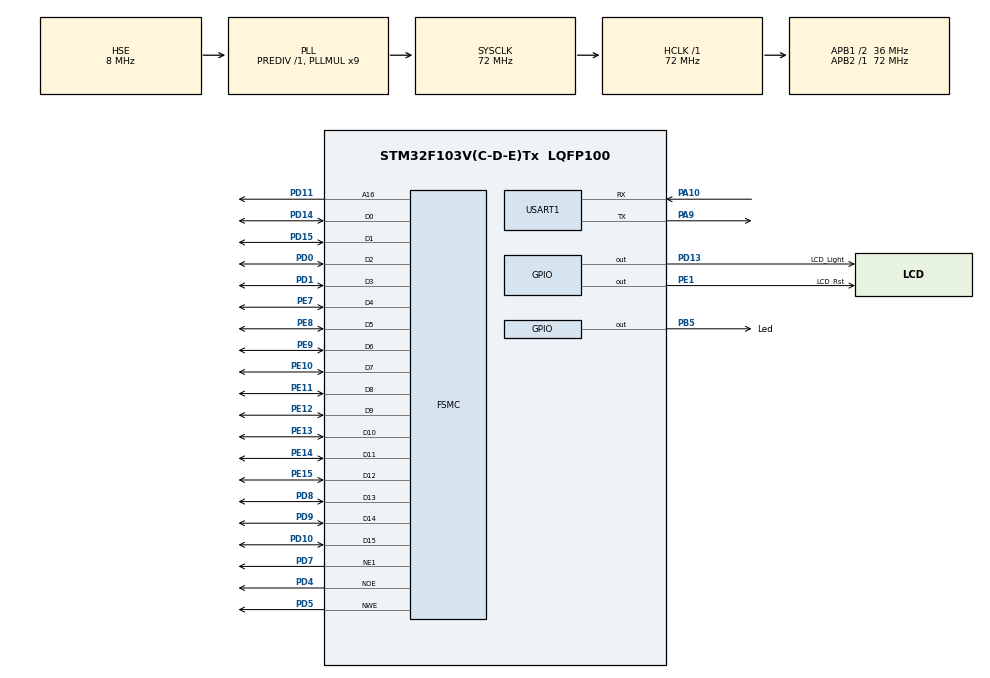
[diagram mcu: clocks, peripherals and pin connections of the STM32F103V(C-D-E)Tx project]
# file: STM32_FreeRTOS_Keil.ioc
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ADC1.Channel-0\#ChannelRegularConversion=ADC_CHANNEL_TEMPSENSOR
ADC1.NbrOfConversionFlag=1
ADC1.Rank-0\#ChannelRegularConversion=1
ADC1.SamplingTime-0\#ChannelRegularConversion=ADC_SAMPLETIME_1CYCLE_5
ADC1.master=1
FREERTOS.Tasks01=defaultTask,0,128,StartDefaultTask,Default,NULL
FSMC.AddressSetupTime1=0x02
FSMC.BusTurnAroundDuration1=0x00
FSMC.DataSetupTime1=0x05
Mcu.Family=STM32F1
Mcu.Name=STM32F103V(C-D-E)Tx
Mcu.Package=LQFP100
NVIC.PriorityGroup=NVIC_PRIORITYGROUP_4
NVIC.TIM1_UP_IRQn=true\:0\:0\:false\:false\:true\:false\:false\:true
NVIC.TimeBase=TIM1_UP_IRQn
NVIC.TimeBaseIP=TIM1
OSC_IN.Mode=HSE-External-Oscillator
OSC_IN.Signal=RCC_OSC_IN
OSC_OUT.Mode=HSE-External-Oscillator
OSC_OUT.Signal=RCC_OSC_OUT
PA10.Mode=Asynchronous
PA10.Signal=USART1_RX
PA9.Mode=Asynchronous
PA9.Signal=USART1_TX
PB5.GPIO_Label=Led
PB5.Signal=GPIO_Output
PC14-OSC32_IN.Mode=LSE-External-Oscillator
PC14-OSC32_IN.Signal=RCC_OSC32_IN
PC15-OSC32_OUT.Mode=LSE-External-Oscillator
PC15-OSC32_OUT.Signal=RCC_OSC32_OUT
PD0.Mode=16b-d1
PD0.Signal=FSMC_D2
PD1.Mode=16b-d1
PD1.Signal=FSMC_D3
PD10.Mode=16b-d1
PD10.Signal=FSMC_D15
PD11.Mode=A16_1
PD11.Signal=FSMC_A16
PD13.GPIO_Label=LCD_Light
PD13.GPIO_Speed=GPIO_SPEED_FREQ_HIGH
PD13.Signal=GPIO_Output
PD14.Mode=16b-d1
PD14.Signal=FSMC_D0
PD15.Mode=16b-d1
PD15.Signal=FSMC_D1
PD4.Mode=Lcd1
PD4.Signal=FSMC_NOE
PD5.Mode=Lcd1
PD5.Signal=FSMC_NWE
PD7.Mode=NorPsramChipSelect1_1
PD7.Signal=FSMC_NE1
PD8.Mode=16b-d1
PD8.Signal=FSMC_D13
PD9.Mode=16b-d1
PD9.Signal=FSMC_D14
PE1.GPIO_Label=LCD_Rst
PE1.Signal=GPIO_Output
PE10.Mode=16b-d1
PE10.Signal=FSMC_D7
PE11.Mode=16b-d1
PE11.Signal=FSMC_D8
PE12.Mode=16b-d1
PE12.Signal=FSMC_D9
PE13.Mode=16b-d1
PE13.Signal=FSMC_D10
PE14.Mode=16b-d1
PE14.Signal=FSMC_D11
PE15.Mode=16b-d1
PE15.Signal=FSMC_D12
PE7.Mode=16b-d1
PE7.Signal=FSMC_D4
PE8.Mode=16b-d1
PE8.Signal=FSMC_D5
PE9.Mode=16b-d1
PE9.Signal=FSMC_D6
ProjectManager.HeapSize=0x200
ProjectManager.StackSize=0x400
ProjectManager.TargetToolchain=MDK-ARM V5
RCC.ADCPresc=RCC_ADCPCLK2_DIV6
RCC.AHBFreq_Value=72000000
RCC.APB1CLKDivider=RCC_HCLK_DIV2
RCC.APB1Freq_Value=36000000
RCC.APB1TimFreq_Value=72000000
RCC.APB2Freq_Value=72000000
RCC.APB2TimFreq_Value=72000000
RCC.HCLKFreq_Value=72000000
RCC.PLLMUL=RCC_PLL_MUL9
RCC.PLLSourceVirtual=RCC_PLLSOURCE_HSE
RCC.SYSCLKFreq_VALUE=72000000
RCC.SYSCLKSource=RCC_SYSCLKSOURCE_PLLCLK
RCC.USBFreq_Value=72000000
RTC.Hours=16
RTC.Minutes=50
USART1.VirtualMode=VM_ASYNC
VP_ADC1_TempSens_Input.Mode=IN-TempSens
VP_FREERTOS_VS_CMSIS_V1.Mode=CMSIS_V1
VP_RTC_VS_RTC_Activate.Mode=RTC_Enabled
VP_RTC_VS_RTC_Calendar.Mode=RTC_Calendar
VP_SYS_VS_ND.Mode=No_Debug
VP_SYS_VS_tim1.Mode=TIM1
board=custom

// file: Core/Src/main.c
/* USER CODE BEGIN Header */
/**
  ******************************************************************************
  * @file           : main.c
  * @brief          : Main program body
  ******************************************************************************
  * @attention
  *
  * <h2><center>&copy; Copyright (c) 2019 STMicroelectronics.
  * All rights reserved.</center></h2>
  *
  * This software component is licensed by ST under Ultimate Liberty license
  * SLA0044, the "License"; You may not use this file except in compliance with
  * the License. You may obtain a copy of the License at:
  *                             www.st.com/SLA0044
  *
  ******************************************************************************
  */
/* USER CODE END Header */

#include "main.h"
#include "cmsis_os.h"
#include "adc.h"
#include "rtc.h"
#include "usart.h"
#include "gpio.h"
#include "fsmc.h"

/* USER CODE BEGIN Includes */
#include "lcd.h"
#include "spc.h"
/* USER CODE END Includes */

void SystemClock_Config(void);
void MX_FREERTOS_Init(void);

int main(void)
{

  /* MCU Configuration--------------------------------------------------------*/

  /* Reset of all peripherals, Initializes the Flash interface and the Systick. */
  HAL_Init();

  /* Configure the system clock */
  SystemClock_Config();

  /* Initialize all configured peripherals */
  MX_GPIO_Init();
  MX_ADC1_Init();
  MX_FSMC_Init();
  MX_RTC_Init();
  MX_USART1_UART_Init();
  /* USER CODE BEGIN 2 */
  LCD_Init();
  /* USER CODE END 2 */

  /* Call init function for freertos objects (in freertos.c) */
  MX_FREERTOS_Init();
	SPC_Init();

  /* Start scheduler */
  osKernelStart();

  /* We should never get here as control is now taken by the scheduler */

  /* Infinite loop */
  while (1)
  {

  }
}

void SystemClock_Config(void)
{
  RCC_OscInitTypeDef RCC_OscInitStruct = {0};
  RCC_ClkInitTypeDef RCC_ClkInitStruct = {0};
  RCC_PeriphCLKInitTypeDef PeriphClkInit = {0};

  /** Initializes the CPU, AHB and APB busses clocks
  */
  RCC_OscInitStruct.OscillatorType = RCC_OSCILLATORTYPE_LSI|RCC_OSCILLATORTYPE_HSE;
  RCC_OscInitStruct.HSEState = RCC_HSE_ON;
  RCC_OscInitStruct.HSEPredivValue = RCC_HSE_PREDIV_DIV1;
  RCC_OscInitStruct.HSIState = RCC_HSI_ON;
  RCC_OscInitStruct.LSIState = RCC_LSI_ON;
  RCC_OscInitStruct.PLL.PLLState = RCC_PLL_ON;
  RCC_OscInitStruct.PLL.PLLSource = RCC_PLLSOURCE_HSE;
  RCC_OscInitStruct.PLL.PLLMUL = RCC_PLL_MUL9;
  if (HAL_RCC_OscConfig(&RCC_OscInitStruct) != HAL_OK)
  {
    Error_Handler();
  }
  /** Initializes the CPU, AHB and APB busses clocks
  */
  RCC_ClkInitStruct.ClockType = RCC_CLOCKTYPE_HCLK|RCC_CLOCKTYPE_SYSCLK
                              |RCC_CLOCKTYPE_PCLK1|RCC_CLOCKTYPE_PCLK2;
  RCC_ClkInitStruct.SYSCLKSource = RCC_SYSCLKSOURCE_PLLCLK;
  RCC_ClkInitStruct.AHBCLKDivider = RCC_SYSCLK_DIV1;
  RCC_ClkInitStruct.APB1CLKDivider = RCC_HCLK_DIV2;
  RCC_ClkInitStruct.APB2CLKDivider = RCC_HCLK_DIV1;

  if (HAL_RCC_ClockConfig(&RCC_ClkInitStruct, FLASH_LATENCY_2) != HAL_OK)
  {
    Error_Handler();
  }
  PeriphClkInit.PeriphClockSelection = RCC_PERIPHCLK_RTC|RCC_PERIPHCLK_ADC;
  PeriphClkInit.RTCClockSelection = RCC_RTCCLKSOURCE_LSI;
  PeriphClkInit.AdcClockSelection = RCC_ADCPCLK2_DIV6;
  if (HAL_RCCEx_PeriphCLKConfig(&PeriphClkInit) != HAL_OK)
  {
    Error_Handler();
  }
}

void HAL_TIM_PeriodElapsedCallback(TIM_HandleTypeDef *htim)
{
  if (htim->Instance == TIM1) {
    HAL_IncTick();
  }
}

void Error_Handler(void)
{
}

/************************ (C) COPYRIGHT STMicroelectronics *****END OF FILE****/

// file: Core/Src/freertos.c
/* USER CODE BEGIN Header */
/**
  ******************************************************************************
  * File Name          : freertos.c
  * Description        : Code for freertos applications
  ******************************************************************************
  * @attention
  *
  * <h2><center>&copy; Copyright (c) 2019 STMicroelectronics.
  * All rights reserved.</center></h2>
  *
  * This software component is licensed by ST under Ultimate Liberty license
  * SLA0044, the "License"; You may not use this file except in compliance with
  * the License. You may obtain a copy of the License at:
  *                             www.st.com/SLA0044
  *
  ******************************************************************************
  */
/* USER CODE END Header */

#include "FreeRTOS.h"
#include "task.h"
#include "main.h"
#include "cmsis_os.h"

/* USER CODE BEGIN Includes */
#include "spc.h"
/* USER CODE END Includes */

//osThreadId spcLcdUpdateTaskHandle;

// definition of Message
//osMessageQId myQueue01Handle;

// definition of Mutex
//osMutexId mymutex;

// definition of timer
//osTimerId KeyDetectionTimerId;

//void StartDefaultTask(void const * argument);
void MX_FREERTOS_Init(void); /* (MISRA C 2004 rule 8.1) */

void MX_FREERTOS_Init(void) {

  /* USER CODE BEGIN RTOS_MUTEX */
  /* add mutexes, ... */
//	osMutexDef(SampleMutex);
//  mymutex = osMutexCreate (osMutex (SampleMutex));
  /* USER CODE END RTOS_MUTEX */

//	osTimerDef(KeyDetectionTimer, KeyDetectionCallback);
//  KeyDetectionTimerId = osTimerCreate (osTimer(KeyDetectionTimer), osTimerPeriodic, NULL);

//	osTimerStart(KeyDetectionTimerId, KEYDETECTION_PERIOD);

//	osMessageQDef(myQueue01, 4, uint16_t);
//  myQueue01Handle = osMessageCreate(osMessageQ(myQueue01), NULL);

  /* Create the thread(s) */
  /* definition and creation of defaultTask */
//  osThreadDef(spcLcdUpdateTask, LcdUpdateTask, osPriorityBelowNormal, 0, 256);
//  spcLcdUpdateTaskHandle = osThreadCreate(osThread(spcLcdUpdateTask), NULL);

  //vTaskSetApplicationTaskTag(spcTaskHandle, ( void * ) '1' );
}

#if 0
void KeyDetectionCallback(void const * argument)
{
  size_t used = 12;

  HAL_GPIO_TogglePin(Led_GPIO_Port, Led_Pin);
  osMessagePut (myQueue01Handle, used, 100);
}
#endif

/* USER CODE BEGIN Application */
void MonitorDefTask()
{
#if 0
  if( xTaskGetCurrentTaskHandle() == defaultTaskHandle )
  {
    //tftprintf("Entering StartDefaultTask");
    //osDelay(50);
  }
#endif
}

void MonitorMyTask()
{
#if 0
  if( xTaskGetCurrentTaskHandle() == spcTaskHandle )
  {
    //tftprintf("Leaving StartTask02");
    //osDelay(50);
  }
#endif
}
/* USER CODE END Application */

/************************ (C) COPYRIGHT STMicroelectronics *****END OF FILE****/
